# GD32E25x register map
File version: 1.0
CPU: CM23 r1p0, little endian, no MPU, no FPU, 2 interrupt priority bits
Registers are 32-bit, read-write, reset 0x0 unless marked. A register's access mark holds for its fields unless they carry their own. Offsets are from the block's base; [hi:lo] are bit positions; {n}, {i} and the like mark numbered series.

## SPI1 — Serial Peripheral Interface 1
Base 0x40003800
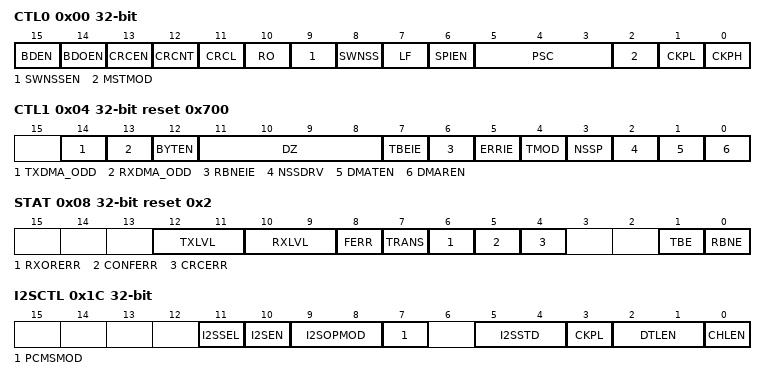
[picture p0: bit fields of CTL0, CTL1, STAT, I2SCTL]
0x00 CTL0 — control register 0
  [15] BDEN — Bidirectional enable
  [14] BDOEN — Bidirectional Transmit output enable
  [13] CRCEN — Hardware CRC calculation enable
  [12] CRCNT — CRC transfer next
  [11] CRCL — CRC length
  [10] RO — Receive only
  [9] SWNSSEN — NSS Software Mode Selection
  [8] SWNSS — NSS Pin Selection In NSS Software Mode
  [7] LF — LSB First Mode
  [6] SPIEN — SPI enable
  [5:3] PSC — Master Clock Prescaler Selection
  [2] MSTMOD — Master Mode Enable
  [1] CKPL — Clock Polarity Selection
  [0] CKPH — Clock Phase Selection
0x04 CTL1 reset 0x700 — control register 1
  [14] TXDMA_ODD — Odd bytes in TX DMA channel
  [13] RXDMA_ODD — Odd bytes in RX DMA channel
  [12] BYTEN — Byte access enable
  [11:8] DZ — Date size
  [7] TBEIE — Transmit Buffer Empty Interrupt Enable
  [6] RBNEIE — Receive Buffer Not Empty Interrupt Enable
  [5] ERRIE — Error interrupt enable
  [4] TMOD — SPI TI Mode Enable
  [3] NSSP — SPI NSS Pulse Mode Enable
  [2] NSSDRV — NSS output enable
  [1] DMATEN — Tx buffer DMA enable
  [0] DMAREN — Rx buffer DMA enable
0x08 STAT access per field reset 0x2 — status register
  [12:11] TXLVL ro — Tx FIFO level
  [10:9] RXLVL ro — Rx FIFO level
  [8] FERR rw — Format Error
  [7] TRANS ro — Transmitting On-going Bit
  [6] RXORERR ro — Reception Overrun Error Bit
  [5] CONFERR ro — SPI Configuration error
  [4] CRCERR rw — SPI CRC Error Bit
  [1] TBE ro — Transmit Buffer Empty
  [0] RBNE ro — Receive Buffer Not Empty
0x0C DATA
  [15:0] DATA
0x10 CPCPOLY reset 0x7 — CRC polynomial register
  [15:0] CRCPOLY
0x14 RCRC ro — RX CRC register
  [15:0] RCRC — RX RCR register
0x18 TCRC ro — TX CRC register
  [15:0] TCRC — Tx CRC register
0x1C I2SCTL — I2S configuration register
  [11] I2SSEL — I2S mode selection
  [10] I2SEN — I2S Enable
  [9:8] I2SOPMOD — I2S configuration mode
  [7] PCMSMOD — PCM frame synchronization
  [5:4] I2SSTD — I2S standard selection
  [3] CKPL — Idle state clock polarity
  [2:1] DTLEN — Data length to be transferred
  [0] CHLEN — Channel length (number of bits per audio channel)
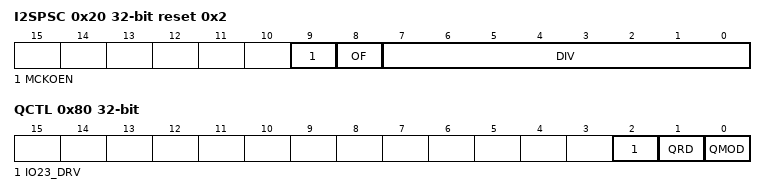
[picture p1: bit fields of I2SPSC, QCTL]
0x20 I2SPSC reset 0x2 — I2S prescaler register
  [9] MCKOEN — I2S_MCK output enable
  [8] OF — Odd factor for the prescaler
  [7:0] DIV — Dividing factor for the prescaler
0x80 QCTL — SPI quad wird control register
  [2] IO23_DRV — Drive IO2 and IO3 enable
  [1] QRD — Quad wire read select
  [0] QMOD — Quad wire mode enable

## SYSCFG — System configuration controller
Base 0x40010000
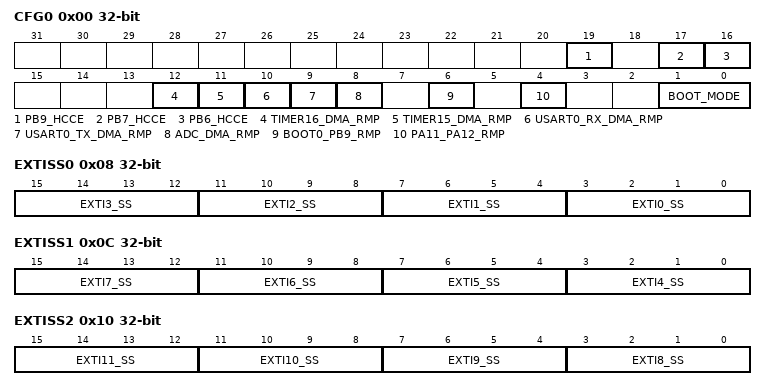
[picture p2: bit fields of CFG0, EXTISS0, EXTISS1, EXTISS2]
0x00 CFG0 — System configuration register 0
  [19] PB9_HCCE — PB9 pin high current capability enable
  [17] PB7_HCCE — PB7 pin high current capability enable
  [16] PB6_HCCE — PB6 pin high current capability enable
  [12] TIMER16_DMA_RMP — Timer 16 DMA request remapping enable
  [11] TIMER15_DMA_RMP — Timer 15 DMA request remapping enable
  [10] USART0_RX_DMA_RMP — USART0_RX DMA request remapping enable
  [9] USART0_TX_DMA_RMP — USART0_TX DMA request remapping enable
  [8] ADC_DMA_RMP — ADC DMA request remapping enable
  [6] BOOT0_PB9_RMP — BOOT0 and PB9 remapping bit
  [4] PA11_PA12_RMP — PA11 and PA12 remapping bit for small packages
  [1:0] BOOT_MODE ro
0x08 EXTISS0 — EXTI sources selection register 0
  [4n+3:4n] EXTI{n}_SS (n=0..3) — EXTI {n} sources selection
0x0C EXTISS1 — EXTI sources selection register 1
  [4n-13:4n-16] EXTI{n}_SS (n=4..7) — EXTI {n} sources selection
0x10 EXTISS2 — EXTI sources selection register 2
  [4n-29:4n-32] EXTI{n}_SS (n=8..11) — EXTI {n} sources selection
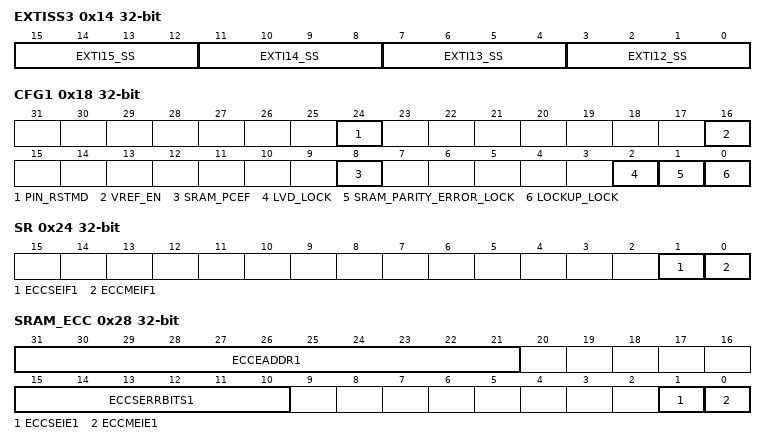
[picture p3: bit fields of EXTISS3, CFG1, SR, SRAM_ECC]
0x14 EXTISS3 — EXTI sources selection register 3
  [4n-45:4n-48] EXTI{n}_SS (n=12..15) — EXTI {n} sources selection
0x18 CFG1 — System configuration register 1
  [24] PIN_RSTMD — Pin reset mode
  [16] VREF_EN — VREF enable
  [8] SRAM_PCEF — SRAM parity check error flag
  [2] LVD_LOCK
  [1] SRAM_PARITY_ERROR_LOCK — SRAM parity check error lock
  [0] LOCKUP_LOCK — Cortex-M4 LOCKUP output lock
0x24 SR — status register
  [1] ECCSEIF1 — SRAM single bit correction event flag
  [0] ECCMEIF1 — SRAM multi bits non-correction event flag
0x28 SRAM_ECC access per field
  [31:21] ECCEADDR1 ro — Indicates the last address of ECC event on SRAM occurred
  [15:10] ECCSERRBITS1 ro — Indicates the error bit
  [1] ECCSEIE1 rw — SRAM single bit correction interrupt enable
  [0] ECCMEIE1 rw — SRAM multi bits non-correction interrupt enable
0x100 CPU_IRQ_LAT — IRQ Latency register
  [7:0] IRQ_LATENCY — specifies the minimum number of cycles between an interrupt
